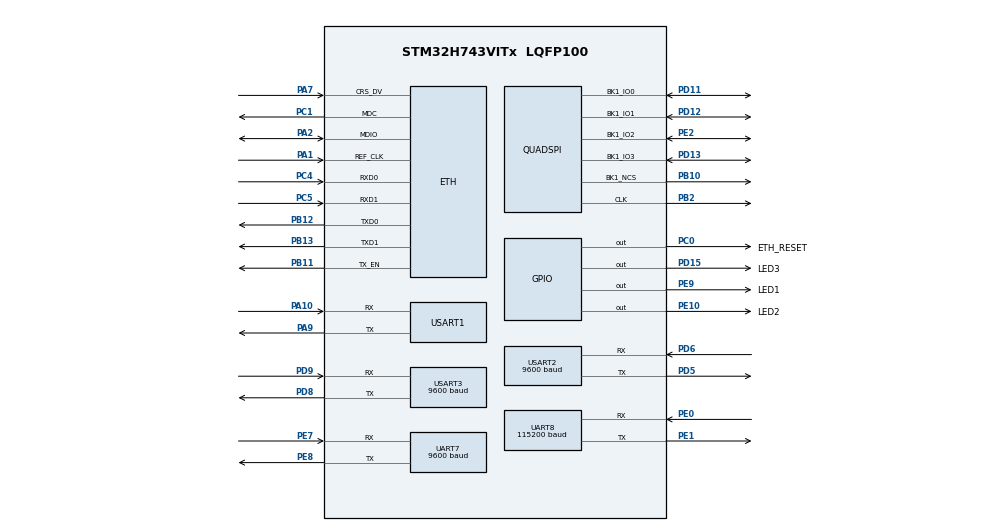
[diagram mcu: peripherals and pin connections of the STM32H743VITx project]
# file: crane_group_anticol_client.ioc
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CORTEX_M7.AccessPermission_S-Cortex_Memory_Protection_Unit_Region1_Settings_S=MPU_REGION_FULL_ACCESS
CORTEX_M7.AccessPermission_S-Cortex_Memory_Protection_Unit_Region2_Settings_S=MPU_REGION_FULL_ACCESS
CORTEX_M7.BaseAddress_S-Cortex_Memory_Protection_Unit_Region1_Settings_S=0x30020000
CORTEX_M7.BaseAddress_S-Cortex_Memory_Protection_Unit_Region2_Settings_S=0x30040000
CORTEX_M7.CPU_DCache=Enabled
CORTEX_M7.CPU_ICache=Enabled
CORTEX_M7.DisableExec_S-Cortex_Memory_Protection_Unit_Region1_Settings_S=MPU_INSTRUCTION_ACCESS_DISABLE
CORTEX_M7.DisableExec_S-Cortex_Memory_Protection_Unit_Region2_Settings_S=MPU_INSTRUCTION_ACCESS_DISABLE
CORTEX_M7.Enable_S-Cortex_Memory_Protection_Unit_Region1_Settings_S=MPU_REGION_ENABLE
CORTEX_M7.Enable_S-Cortex_Memory_Protection_Unit_Region2_Settings_S=MPU_REGION_ENABLE
CORTEX_M7.IsBufferable_S-Cortex_Memory_Protection_Unit_Region2_Settings_S=MPU_ACCESS_BUFFERABLE
CORTEX_M7.IsShareable_S-Cortex_Memory_Protection_Unit_Region2_Settings_S=MPU_ACCESS_SHAREABLE
CORTEX_M7.Size_S-Cortex_Memory_Protection_Unit_Region1_Settings_S=MPU_REGION_SIZE_128KB
CORTEX_M7.Size_S-Cortex_Memory_Protection_Unit_Region2_Settings_S=MPU_REGION_SIZE_512B
CORTEX_M7.TypeExtField_S-Cortex_Memory_Protection_Unit_Region1_Settings_S=MPU_TEX_LEVEL1
CORTEX_M7.default_mode_Activation=1
Dma.Request0=UART7_RX
Dma.Request1=UART7_TX
Dma.Request2=USART1_RX
Dma.Request3=USART1_TX
Dma.Request4=USART2_RX
Dma.Request5=USART2_TX
Dma.Request6=UART8_RX
Dma.Request7=UART8_TX
Dma.Request8=USART3_RX
Dma.Request9=USART3_TX
Dma.UART7_RX.0.Direction=DMA_PERIPH_TO_MEMORY
Dma.UART7_RX.0.EventEnable=DISABLE
Dma.UART7_RX.0.FIFOMode=DMA_FIFOMODE_DISABLE
Dma.UART7_RX.0.Instance=DMA1_Stream0
Dma.UART7_RX.0.MemDataAlignment=DMA_MDATAALIGN_BYTE
Dma.UART7_RX.0.MemInc=DMA_MINC_ENABLE
Dma.UART7_RX.0.Mode=DMA_NORMAL
Dma.UART7_RX.0.PeriphDataAlignment=DMA_PDATAALIGN_BYTE
Dma.UART7_RX.0.PeriphInc=DMA_PINC_DISABLE
Dma.UART7_RX.0.Polarity=HAL_DMAMUX_REQ_GEN_RISING
Dma.UART7_RX.0.Priority=DMA_PRIORITY_VERY_HIGH
Dma.UART7_RX.0.RequestNumber=1
Dma.UART7_RX.0.SignalID=NONE
Dma.UART7_RX.0.SyncEnable=DISABLE
Dma.UART7_RX.0.SyncPolarity=HAL_DMAMUX_SYNC_NO_EVENT
Dma.UART7_RX.0.SyncRequestNumber=1
Dma.UART7_RX.0.SyncSignalID=NONE
Dma.UART7_TX.1.Direction=DMA_MEMORY_TO_PERIPH
Dma.UART7_TX.1.EventEnable=DISABLE
Dma.UART7_TX.1.FIFOMode=DMA_FIFOMODE_DISABLE
Dma.UART7_TX.1.Instance=DMA1_Stream1
Dma.UART7_TX.1.MemDataAlignment=DMA_MDATAALIGN_BYTE
Dma.UART7_TX.1.MemInc=DMA_MINC_ENABLE
Dma.UART7_TX.1.Mode=DMA_NORMAL
Dma.UART7_TX.1.PeriphDataAlignment=DMA_PDATAALIGN_BYTE
Dma.UART7_TX.1.PeriphInc=DMA_PINC_DISABLE
Dma.UART7_TX.1.Polarity=HAL_DMAMUX_REQ_GEN_RISING
Dma.UART7_TX.1.Priority=DMA_PRIORITY_VERY_HIGH
Dma.UART7_TX.1.RequestNumber=1
Dma.UART7_TX.1.SignalID=NONE
Dma.UART7_TX.1.SyncEnable=DISABLE
Dma.UART7_TX.1.SyncPolarity=HAL_DMAMUX_SYNC_NO_EVENT
Dma.UART7_TX.1.SyncRequestNumber=1
Dma.UART7_TX.1.SyncSignalID=NONE
Dma.UART8_RX.6.Direction=DMA_PERIPH_TO_MEMORY
Dma.UART8_RX.6.EventEnable=DISABLE
Dma.UART8_RX.6.FIFOMode=DMA_FIFOMODE_DISABLE
Dma.UART8_RX.6.Instance=DMA1_Stream6
Dma.UART8_RX.6.MemDataAlignment=DMA_MDATAALIGN_BYTE
Dma.UART8_RX.6.MemInc=DMA_MINC_ENABLE
Dma.UART8_RX.6.Mode=DMA_NORMAL
Dma.UART8_RX.6.PeriphDataAlignment=DMA_PDATAALIGN_BYTE
Dma.UART8_RX.6.PeriphInc=DMA_PINC_DISABLE
Dma.UART8_RX.6.Polarity=HAL_DMAMUX_REQ_GEN_RISING
Dma.UART8_RX.6.Priority=DMA_PRIORITY_LOW
Dma.UART8_RX.6.RequestNumber=1
Dma.UART8_RX.6.SignalID=NONE
Dma.UART8_RX.6.SyncEnable=DISABLE
Dma.UART8_RX.6.SyncPolarity=HAL_DMAMUX_SYNC_NO_EVENT
Dma.UART8_RX.6.SyncRequestNumber=1
Dma.UART8_RX.6.SyncSignalID=NONE
Dma.UART8_TX.7.Direction=DMA_MEMORY_TO_PERIPH
Dma.UART8_TX.7.EventEnable=DISABLE
Dma.UART8_TX.7.FIFOMode=DMA_FIFOMODE_DISABLE
Dma.UART8_TX.7.Instance=DMA1_Stream7
Dma.UART8_TX.7.MemDataAlignment=DMA_MDATAALIGN_BYTE
Dma.UART8_TX.7.MemInc=DMA_MINC_ENABLE
Dma.UART8_TX.7.Mode=DMA_NORMAL
Dma.UART8_TX.7.PeriphDataAlignment=DMA_PDATAALIGN_BYTE
Dma.UART8_TX.7.PeriphInc=DMA_PINC_DISABLE
Dma.UART8_TX.7.Polarity=HAL_DMAMUX_REQ_GEN_RISING
Dma.UART8_TX.7.Priority=DMA_PRIORITY_LOW
Dma.UART8_TX.7.RequestNumber=1
Dma.UART8_TX.7.SignalID=NONE
Dma.UART8_TX.7.SyncEnable=DISABLE
Dma.UART8_TX.7.SyncPolarity=HAL_DMAMUX_SYNC_NO_EVENT
Dma.UART8_TX.7.SyncRequestNumber=1
Dma.UART8_TX.7.SyncSignalID=NONE
Dma.USART1_RX.2.Direction=DMA_PERIPH_TO_MEMORY
Dma.USART1_RX.2.EventEnable=DISABLE
Dma.USART1_RX.2.FIFOMode=DMA_FIFOMODE_DISABLE
Dma.USART1_RX.2.Instance=DMA1_Stream2
Dma.USART1_RX.2.MemDataAlignment=DMA_MDATAALIGN_BYTE
Dma.USART1_RX.2.MemInc=DMA_MINC_ENABLE
Dma.USART1_RX.2.Mode=DMA_NORMAL
Dma.USART1_RX.2.PeriphDataAlignment=DMA_PDATAALIGN_BYTE
Dma.USART1_RX.2.PeriphInc=DMA_PINC_DISABLE
Dma.USART1_RX.2.Polarity=HAL_DMAMUX_REQ_GEN_RISING
Dma.USART1_RX.2.Priority=DMA_PRIORITY_LOW
Dma.USART1_RX.2.RequestNumber=1
Dma.USART1_RX.2.SignalID=NONE
Dma.USART1_RX.2.SyncEnable=DISABLE
Dma.USART1_RX.2.SyncPolarity=HAL_DMAMUX_SYNC_NO_EVENT
Dma.USART1_RX.2.SyncRequestNumber=1
Dma.USART1_RX.2.SyncSignalID=NONE
Dma.USART1_TX.3.Direction=DMA_MEMORY_TO_PERIPH
Dma.USART1_TX.3.EventEnable=DISABLE
Dma.USART1_TX.3.FIFOMode=DMA_FIFOMODE_DISABLE
Dma.USART1_TX.3.Instance=DMA1_Stream3
Dma.USART1_TX.3.MemDataAlignment=DMA_MDATAALIGN_BYTE
Dma.USART1_TX.3.MemInc=DMA_MINC_ENABLE
Dma.USART1_TX.3.Mode=DMA_NORMAL
Dma.USART1_TX.3.PeriphDataAlignment=DMA_PDATAALIGN_BYTE
Dma.USART1_TX.3.PeriphInc=DMA_PINC_DISABLE
Dma.USART1_TX.3.Polarity=HAL_DMAMUX_REQ_GEN_RISING
Dma.USART1_TX.3.Priority=DMA_PRIORITY_LOW
Dma.USART1_TX.3.RequestNumber=1
Dma.USART1_TX.3.SignalID=NONE
Dma.USART1_TX.3.SyncEnable=DISABLE
Dma.USART1_TX.3.SyncPolarity=HAL_DMAMUX_SYNC_NO_EVENT
Dma.USART1_TX.3.SyncRequestNumber=1
Dma.USART1_TX.3.SyncSignalID=NONE
Dma.USART2_RX.4.Direction=DMA_PERIPH_TO_MEMORY
Dma.USART2_RX.4.EventEnable=DISABLE
Dma.USART2_RX.4.FIFOMode=DMA_FIFOMODE_DISABLE
Dma.USART2_RX.4.Instance=DMA1_Stream4
Dma.USART2_RX.4.MemDataAlignment=DMA_MDATAALIGN_BYTE
Dma.USART2_RX.4.MemInc=DMA_MINC_ENABLE
Dma.USART2_RX.4.Mode=DMA_NORMAL
Dma.USART2_RX.4.PeriphDataAlignment=DMA_PDATAALIGN_BYTE
Dma.USART2_RX.4.PeriphInc=DMA_PINC_DISABLE
Dma.USART2_RX.4.Polarity=HAL_DMAMUX_REQ_GEN_RISING
Dma.USART2_RX.4.Priority=DMA_PRIORITY_HIGH
Dma.USART2_RX.4.RequestNumber=1
Dma.USART2_RX.4.SignalID=NONE
Dma.USART2_RX.4.SyncEnable=DISABLE
Dma.USART2_RX.4.SyncPolarity=HAL_DMAMUX_SYNC_NO_EVENT
Dma.USART2_RX.4.SyncRequestNumber=1
Dma.USART2_RX.4.SyncSignalID=NONE
Dma.USART2_TX.5.Direction=DMA_MEMORY_TO_PERIPH
Dma.USART2_TX.5.EventEnable=DISABLE
Dma.USART2_TX.5.FIFOMode=DMA_FIFOMODE_DISABLE
Dma.USART2_TX.5.Instance=DMA1_Stream5
Dma.USART2_TX.5.MemDataAlignment=DMA_MDATAALIGN_BYTE
Dma.USART2_TX.5.MemInc=DMA_MINC_ENABLE
Dma.USART2_TX.5.Mode=DMA_NORMAL
Dma.USART2_TX.5.PeriphDataAlignment=DMA_PDATAALIGN_BYTE
Dma.USART2_TX.5.PeriphInc=DMA_PINC_DISABLE
Dma.USART2_TX.5.Polarity=HAL_DMAMUX_REQ_GEN_RISING
Dma.USART2_TX.5.Priority=DMA_PRIORITY_HIGH
Dma.USART2_TX.5.RequestNumber=1
Dma.USART2_TX.5.SignalID=NONE
Dma.USART2_TX.5.SyncEnable=DISABLE
Dma.USART2_TX.5.SyncPolarity=HAL_DMAMUX_SYNC_NO_EVENT
Dma.USART2_TX.5.SyncRequestNumber=1
Dma.USART2_TX.5.SyncSignalID=NONE
Dma.USART3_RX.8.Direction=DMA_PERIPH_TO_MEMORY
Dma.USART3_RX.8.EventEnable=DISABLE
Dma.USART3_RX.8.FIFOMode=DMA_FIFOMODE_DISABLE
Dma.USART3_RX.8.Instance=DMA2_Stream0
Dma.USART3_RX.8.MemDataAlignment=DMA_MDATAALIGN_BYTE
Dma.USART3_RX.8.MemInc=DMA_MINC_ENABLE
Dma.USART3_RX.8.Mode=DMA_NORMAL
Dma.USART3_RX.8.PeriphDataAlignment=DMA_PDATAALIGN_BYTE
Dma.USART3_RX.8.PeriphInc=DMA_PINC_DISABLE
Dma.USART3_RX.8.Polarity=HAL_DMAMUX_REQ_GEN_RISING
Dma.USART3_RX.8.Priority=DMA_PRIORITY_LOW
Dma.USART3_RX.8.RequestNumber=1
Dma.USART3_RX.8.SignalID=NONE
Dma.USART3_RX.8.SyncEnable=DISABLE
Dma.USART3_RX.8.SyncPolarity=HAL_DMAMUX_SYNC_NO_EVENT
Dma.USART3_RX.8.SyncRequestNumber=1
Dma.USART3_RX.8.SyncSignalID=NONE
Dma.USART3_TX.9.Direction=DMA_MEMORY_TO_PERIPH
Dma.USART3_TX.9.EventEnable=DISABLE
Dma.USART3_TX.9.FIFOMode=DMA_FIFOMODE_DISABLE
Dma.USART3_TX.9.Instance=DMA2_Stream1
Dma.USART3_TX.9.MemDataAlignment=DMA_MDATAALIGN_BYTE
Dma.USART3_TX.9.MemInc=DMA_MINC_ENABLE
Dma.USART3_TX.9.Mode=DMA_NORMAL
Dma.USART3_TX.9.PeriphDataAlignment=DMA_PDATAALIGN_BYTE
Dma.USART3_TX.9.PeriphInc=DMA_PINC_DISABLE
Dma.USART3_TX.9.Polarity=HAL_DMAMUX_REQ_GEN_RISING
Dma.USART3_TX.9.Priority=DMA_PRIORITY_LOW
Dma.USART3_TX.9.RequestNumber=1
Dma.USART3_TX.9.SignalID=NONE
Dma.USART3_TX.9.SyncEnable=DISABLE
Dma.USART3_TX.9.SyncPolarity=HAL_DMAMUX_SYNC_NO_EVENT
Dma.USART3_TX.9.SyncRequestNumber=1
Dma.USART3_TX.9.SyncSignalID=NONE
ETH.MediaInterface=HAL_ETH_RMII_MODE
FREERTOS.Tasks01=defaultTask,24,2048,StartDefaultTask,Default,NULL,Dynamic,NULL,NULL
FREERTOS.configCHECK_FOR_STACK_OVERFLOW=1
FREERTOS.configTOTAL_HEAP_SIZE=131072
FREERTOS.configUSE_NEWLIB_REENTRANT=1
IWDG1.Prescaler=IWDG_PRESCALER_256
LWIP.BSP.number=1
LWIP.DEFAULT_ACCEPTMBOX_SIZE=12
LWIP.GATEWAY_ADDRESS=192.168.042.001
LWIP.IP_ADDRESS=192.168.042.033
LWIP.LWIP_DHCP=1
LWIP.LWIP_DNS=1
LWIP.LWIP_RAM_HEAP_POINTER=0x30020000
LWIP.LWIP_SNTP=1
LWIP.LWIP_SO_RCVTIMEO=1
LWIP.LWIP_SO_SNDTIMEO=1
LWIP.LWIP_TCPIP_CORE_LOCKING=1
LWIP.LWIP_TCP_KEEPALIVE=1
LWIP.MEMP_NUM_NETCONN=15
LWIP.MEMP_NUM_SYS_TIMEOUT=20
LWIP.MEMP_NUM_TCP_PCB=20
LWIP.MEMP_NUM_TCP_SEG=17
LWIP.MEMP_NUM_UDP_PCB=20
LWIP.MEM_SIZE=131048
LWIP.NETMASK_ADDRESS=255.255.255.000
LWIP.SO_REUSE=1
LWIP.TCPIP_THREAD_STACKSIZE=4096
LWIP.TCP_MSS=1460
LWIP.TCP_SND_BUF=5840
LWIP.TCP_WND_UPDATE_THRESHOLD=1460
LWIP.Version=v2.1.2_Cube
LWIP0.BSP.STBoard=false
LWIP0.BSP.api=BSP_COMPONENT_DRIVER
LWIP0.BSP.component=LAN8742
LWIP0.BSP.instance=LAN8742
LWIP0.BSP.name=Driver_PHY
LWIP0.BSP.semaphore=S_LAN8742
LWIP0.BSP.solution=LAN8742
Mcu.Family=STM32H7
Mcu.Name=STM32H743VITx
Mcu.Package=LQFP100
NVIC.DMA1_Stream0_IRQn=true\:5\:0\:false\:false\:true\:true\:false\:true\:true
NVIC.DMA1_Stream1_IRQn=true\:5\:0\:false\:false\:true\:true\:false\:true\:true
NVIC.DMA1_Stream2_IRQn=true\:5\:0\:false\:false\:true\:true\:false\:true\:true
NVIC.DMA1_Stream3_IRQn=true\:5\:0\:false\:false\:true\:true\:false\:true\:true
NVIC.DMA1_Stream4_IRQn=true\:5\:0\:false\:false\:true\:true\:false\:true\:true
NVIC.DMA1_Stream5_IRQn=true\:5\:0\:false\:false\:true\:true\:false\:true\:true
NVIC.DMA1_Stream6_IRQn=true\:5\:0\:false\:false\:true\:true\:false\:true\:true
NVIC.DMA1_Stream7_IRQn=true\:5\:0\:false\:false\:true\:true\:false\:true\:true
NVIC.DMA2_Stream0_IRQn=true\:5\:0\:false\:false\:true\:true\:false\:true\:true
NVIC.DMA2_Stream1_IRQn=true\:5\:0\:false\:false\:true\:true\:false\:true\:true
NVIC.ETH_IRQn=true\:5\:0\:false\:false\:true\:true\:true\:true\:true
NVIC.PriorityGroup=NVIC_PRIORITYGROUP_4
NVIC.TIM6_DAC_IRQn=true\:15\:0\:false\:false\:true\:false\:false\:true\:true
NVIC.TimeBase=TIM6_DAC_IRQn
NVIC.TimeBaseIP=TIM6
NVIC.UART7_IRQn=true\:5\:0\:false\:false\:true\:true\:true\:true\:true
NVIC.UART8_IRQn=true\:5\:0\:false\:false\:true\:true\:true\:true\:true
NVIC.USART1_IRQn=true\:5\:0\:false\:false\:true\:true\:true\:true\:true
NVIC.USART2_IRQn=true\:5\:0\:false\:false\:true\:true\:true\:true\:true
NVIC.USART3_IRQn=true\:5\:0\:false\:false\:true\:true\:true\:true\:true
PA1.GPIO_Speed=GPIO_SPEED_FREQ_VERY_HIGH
PA1.Mode=RMII
PA1.Signal=ETH_REF_CLK
PA10.Mode=Asynchronous
PA10.Signal=USART1_RX
PA2.GPIO_Speed=GPIO_SPEED_FREQ_VERY_HIGH
PA2.Mode=RMII
PA2.Signal=ETH_MDIO
PA7.GPIO_Speed=GPIO_SPEED_FREQ_VERY_HIGH
PA7.Mode=RMII
PA7.Signal=ETH_CRS_DV
PA9.Mode=Asynchronous
PA9.Signal=USART1_TX
PB10.GPIO_Speed=GPIO_SPEED_FREQ_VERY_HIGH
PB10.Mode=Single Bank 1
PB10.Signal=QUADSPI_BK1_NCS
PB11.GPIO_Speed=GPIO_SPEED_FREQ_VERY_HIGH
PB11.Mode=RMII
PB11.Signal=ETH_TX_EN
PB12.GPIO_Speed=GPIO_SPEED_FREQ_VERY_HIGH
PB12.Mode=RMII
PB12.Signal=ETH_TXD0
PB13.GPIO_Speed=GPIO_SPEED_FREQ_VERY_HIGH
PB13.Mode=RMII
PB13.Signal=ETH_TXD1
PB2.GPIO_Speed=GPIO_SPEED_FREQ_VERY_HIGH
PB2.Mode=Single Bank 1
PB2.Signal=QUADSPI_CLK
PC0.GPIO_Label=ETH_RESET
PC0.Signal=GPIO_Output
PC1.GPIO_Speed=GPIO_SPEED_FREQ_VERY_HIGH
PC1.Mode=RMII
PC1.Signal=ETH_MDC
PC4.GPIO_Speed=GPIO_SPEED_FREQ_VERY_HIGH
PC4.Mode=RMII
PC4.Signal=ETH_RXD0
PC5.GPIO_Speed=GPIO_SPEED_FREQ_VERY_HIGH
PC5.Mode=RMII
PC5.Signal=ETH_RXD1
PD11.GPIO_Speed=GPIO_SPEED_FREQ_VERY_HIGH
PD11.Mode=Single Bank 1
PD11.Signal=QUADSPI_BK1_IO0
PD12.GPIO_Speed=GPIO_SPEED_FREQ_VERY_HIGH
PD12.Mode=Single Bank 1
PD12.Signal=QUADSPI_BK1_IO1
PD13.GPIO_Speed=GPIO_SPEED_FREQ_VERY_HIGH
PD13.Mode=Single Bank 1
PD13.Signal=QUADSPI_BK1_IO3
PD15.GPIO_Label=LED3
PD15.Signal=GPIO_Output
PD5.GPIO_Speed=GPIO_SPEED_FREQ_VERY_HIGH
PD5.Mode=Asynchronous
PD5.Signal=USART2_TX
PD6.GPIO_Speed=GPIO_SPEED_FREQ_VERY_HIGH
PD6.Mode=Asynchronous
PD6.Signal=USART2_RX
PD8.Mode=Asynchronous
PD8.Signal=USART3_TX
PD9.Mode=Asynchronous
PD9.Signal=USART3_RX
PE0.Mode=Asynchronous
PE0.Signal=UART8_RX
PE1.Mode=Asynchronous
PE1.Signal=UART8_TX
PE10.GPIO_Label=LED2
PE10.GPIO_PuPd=GPIO_PULLUP
PE10.PinState=GPIO_PIN_SET
PE10.Signal=GPIO_Output
PE2.GPIO_Speed=GPIO_SPEED_FREQ_VERY_HIGH
PE2.Mode=Single Bank 1
PE2.Signal=QUADSPI_BK1_IO2
PE7.Mode=Asynchronous
PE7.Signal=UART7_RX
PE8.Mode=Asynchronous
PE8.Signal=UART7_TX
PE9.GPIO_Label=LED1
PE9.GPIO_PuPd=GPIO_PULLUP
PE9.PinState=GPIO_PIN_SET
PE9.Signal=GPIO_Output
PH0-OSC_IN\ (PH0).Mode=HSE-External-Clock-Source
PH0-OSC_IN\ (PH0).Signal=RCC_OSC_IN
ProjectManager.HeapSize=0x4000
ProjectManager.StackSize=0x4000
ProjectManager.TargetToolchain=STM32CubeIDE
QUADSPI.ChipSelectHighTime=QSPI_CS_HIGH_TIME_2_CYCLE
QUADSPI.ClockPrescaler=2
QUADSPI.FlashSize=24
QUADSPI.SampleShifting=QSPI_SAMPLE_SHIFTING_HALFCYCLE
RCC.ADCFreq_Value=100000000
RCC.APB1Freq_Value=100000000
RCC.APB2Freq_Value=100000000
RCC.APB3Freq_Value=100000000
RCC.APB4Freq_Value=100000000
RCC.CortexFreq_Value=400000000
RCC.D1PPRE=RCC_APB3_DIV2
RCC.D2PPRE1=RCC_APB1_DIV2
RCC.D2PPRE2=RCC_APB2_DIV2
RCC.D3PPRE=RCC_APB4_DIV2
RCC.DIVN1=400
RCC.DIVN2=100
RCC.DIVN3=30
RCC.HCLKFreq_Value=200000000
RCC.HPRE=RCC_HCLK_DIV2
RCC.SYSCLKFreq_VALUE=400000000
RCC.SYSCLKSource=RCC_SYSCLKSOURCE_PLLCLK
RCC.USBFreq_Value=400000000
UART7.BaudRate=9600
UART8.BaudRate=115200
USART1.VirtualMode-Asynchronous=VM_ASYNC
USART2.BaudRate=9600
USART2.Parity=PARITY_EVEN
USART2.VirtualMode-Asynchronous=VM_ASYNC
USART2.WordLength=WORDLENGTH_9B
USART3.BaudRate=9600
USART3.Parity=PARITY_EVEN
USART3.VirtualMode-Asynchronous=VM_ASYNC
USART3.WordLength=WORDLENGTH_9B
VP_FREERTOS_VS_CMSIS_V2.Mode=CMSIS_V2
VP_IWDG1_VS_IWDG.Mode=IWDG_Activate
VP_LWIP_VS_Enabled.Mode=Enabled
VP_MEMORYMAP_VS_MEMORYMAP.Mode=CurAppReg
VP_RTC_VS_RTC_Activate.Mode=RTC_Enabled
VP_RTC_VS_RTC_Calendar.Mode=RTC_Calendar
VP_SYS_VS_tim6.Mode=TIM6
board=custom

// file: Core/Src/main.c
/* USER CODE BEGIN Header */
/**
 ******************************************************************************
 * @file           : main.c
 * @brief          : Main program body
 ******************************************************************************
 * @attention
 *
 * Copyright (c) 2025 STMicroelectronics.
 * All rights reserved.
 *
 * This software is licensed under terms that can be found in the LICENSE file
 * in the root directory of this software component.
 * If no LICENSE file comes with this software, it is provided AS-IS.
 *
 ******************************************************************************
 */
/* USER CODE END Header */
#include "main.h"
#include "cmsis_os.h"

/* USER CODE BEGIN Includes */
#include "board_manage.h"
/* USER CODE END Includes */

/* USER CODE BEGIN PD */
#define LOG_D(fmt, ...) // printf("[D][%s:%d] " fmt, __func__, __LINE__, ##__VA_ARGS__)
#define LOG_I(fmt, ...) printf("[I][%s:%d] " fmt, __func__, __LINE__, ##__VA_ARGS__)
#define LOG_E(fmt, ...) printf("[E][%s:%d] " fmt, __func__, __LINE__, ##__VA_ARGS__)
/* USER CODE END PD */

IWDG_HandleTypeDef hiwdg1;

QSPI_HandleTypeDef hqspi;

RTC_HandleTypeDef hrtc;

UART_HandleTypeDef huart7;
UART_HandleTypeDef huart8;
UART_HandleTypeDef huart1;
UART_HandleTypeDef huart2;
UART_HandleTypeDef huart3;
DMA_HandleTypeDef hdma_uart7_rx;
DMA_HandleTypeDef hdma_uart7_tx;
DMA_HandleTypeDef hdma_uart8_rx;
DMA_HandleTypeDef hdma_uart8_tx;
DMA_HandleTypeDef hdma_usart1_rx;
DMA_HandleTypeDef hdma_usart1_tx;
DMA_HandleTypeDef hdma_usart2_rx;
DMA_HandleTypeDef hdma_usart2_tx;
DMA_HandleTypeDef hdma_usart3_rx;
DMA_HandleTypeDef hdma_usart3_tx;

/* Definitions for defaultTask */
osThreadId_t defaultTaskHandle;
const osThreadAttr_t defaultTask_attributes = {
  .name = "defaultTask",
  .stack_size = 2048 * 4,
  .priority = (osPriority_t) osPriorityNormal,
};

void SystemClock_Config(void);
static void MPU_Config(void);
static void MX_GPIO_Init(void);
static void MX_DMA_Init(void);
static void MX_USART1_UART_Init(void);
static void MX_UART7_Init(void);
static void MX_UART8_Init(void);
static void MX_USART2_UART_Init(void);
static void MX_USART3_UART_Init(void);
static void MX_RTC_Init(void);
static void MX_QUADSPI_Init(void);
static void MX_IWDG1_Init(void);
void StartDefaultTask(void *argument);

int main(void)
{

  /* MPU Configuration--------------------------------------------------------*/
  MPU_Config();

  /* Enable the CPU Cache */

  /* Enable I-Cache---------------------------------------------------------*/
  SCB_EnableICache();

  /* Enable D-Cache---------------------------------------------------------*/
  SCB_EnableDCache();

  /* MCU Configuration--------------------------------------------------------*/

  /* Reset of all peripherals, Initializes the Flash interface and the Systick. */
  HAL_Init();

  /* Configure the system clock */
  SystemClock_Config();

  /* Initialize all configured peripherals */
  MX_GPIO_Init();
  MX_DMA_Init();
  MX_USART1_UART_Init();
  MX_UART7_Init();
  MX_UART8_Init();
  MX_USART2_UART_Init();
  MX_USART3_UART_Init();
  MX_RTC_Init();
  MX_QUADSPI_Init();
  MX_IWDG1_Init();
  /* USER CODE BEGIN 2 */
  board_setup_components();
  /* USER CODE END 2 */

  /* Init scheduler */
  osKernelInitialize();

  /* Create the thread(s) */
  /* creation of defaultTask */
  defaultTaskHandle = osThreadNew(StartDefaultTask, NULL, &defaultTask_attributes);

  /* USER CODE BEGIN RTOS_THREADS */
  /* add threads, ... */
  board_create_user_tasks();
  /* USER CODE END RTOS_THREADS */

  /* Start scheduler */
  osKernelStart();

  /* We should never get here as control is now taken by the scheduler */

  /* Infinite loop */
  while (1)
  {

  }
}

void SystemClock_Config(void)
{
  RCC_OscInitTypeDef RCC_OscInitStruct = {0};
  RCC_ClkInitTypeDef RCC_ClkInitStruct = {0};

  /** Supply configuration update enable
  */
  HAL_PWREx_ConfigSupply(PWR_LDO_SUPPLY);

  /** Configure the main internal regulator output voltage
  */
  __HAL_PWR_VOLTAGESCALING_CONFIG(PWR_REGULATOR_VOLTAGE_SCALE1);

  while(!__HAL_PWR_GET_FLAG(PWR_FLAG_VOSRDY)) {}

  /** Initializes the RCC Oscillators according to the specified parameters
  * in the RCC_OscInitTypeDef structure.
  */
  RCC_OscInitStruct.OscillatorType = RCC_OSCILLATORTYPE_HSI|RCC_OSCILLATORTYPE_LSI;
  RCC_OscInitStruct.HSIState = RCC_HSI_DIV1;
  RCC_OscInitStruct.HSICalibrationValue = RCC_HSICALIBRATION_DEFAULT;
  RCC_OscInitStruct.LSIState = RCC_LSI_ON;
  RCC_OscInitStruct.PLL.PLLState = RCC_PLL_ON;
  RCC_OscInitStruct.PLL.PLLSource = RCC_PLLSOURCE_HSI;
  RCC_OscInitStruct.PLL.PLLM = 32;
  RCC_OscInitStruct.PLL.PLLN = 400;
  RCC_OscInitStruct.PLL.PLLP = 2;
  RCC_OscInitStruct.PLL.PLLQ = 2;
  RCC_OscInitStruct.PLL.PLLR = 2;
  RCC_OscInitStruct.PLL.PLLRGE = RCC_PLL1VCIRANGE_1;
  RCC_OscInitStruct.PLL.PLLVCOSEL = RCC_PLL1VCOWIDE;
  RCC_OscInitStruct.PLL.PLLFRACN = 0;
  if (HAL_RCC_OscConfig(&RCC_OscInitStruct) != HAL_OK)
  {
    Error_Handler();
  }

  /** Initializes the CPU, AHB and APB buses clocks
  */
  RCC_ClkInitStruct.ClockType = RCC_CLOCKTYPE_HCLK|RCC_CLOCKTYPE_SYSCLK
                              |RCC_CLOCKTYPE_PCLK1|RCC_CLOCKTYPE_PCLK2
                              |RCC_CLOCKTYPE_D3PCLK1|RCC_CLOCKTYPE_D1PCLK1;
  RCC_ClkInitStruct.SYSCLKSource = RCC_SYSCLKSOURCE_PLLCLK;
  RCC_ClkInitStruct.SYSCLKDivider = RCC_SYSCLK_DIV1;
  RCC_ClkInitStruct.AHBCLKDivider = RCC_HCLK_DIV2;
  RCC_ClkInitStruct.APB3CLKDivider = RCC_APB3_DIV2;
  RCC_ClkInitStruct.APB1CLKDivider = RCC_APB1_DIV2;
  RCC_ClkInitStruct.APB2CLKDivider = RCC_APB2_DIV2;
  RCC_ClkInitStruct.APB4CLKDivider = RCC_APB4_DIV2;

  if (HAL_RCC_ClockConfig(&RCC_ClkInitStruct, FLASH_LATENCY_2) != HAL_OK)
  {
    Error_Handler();
  }
}

static void MX_IWDG1_Init(void)
{

  hiwdg1.Instance = IWDG1;
  hiwdg1.Init.Prescaler = IWDG_PRESCALER_256;
  hiwdg1.Init.Window = 4095;
  hiwdg1.Init.Reload = 4095;
  if (HAL_IWDG_Init(&hiwdg1) != HAL_OK)
  {
    Error_Handler();
  }

}

static void MX_QUADSPI_Init(void)
{

  /* QUADSPI parameter configuration*/
  hqspi.Instance = QUADSPI;
  hqspi.Init.ClockPrescaler = 2;
  hqspi.Init.FifoThreshold = 1;
  hqspi.Init.SampleShifting = QSPI_SAMPLE_SHIFTING_HALFCYCLE;
  hqspi.Init.FlashSize = 24;
  hqspi.Init.ChipSelectHighTime = QSPI_CS_HIGH_TIME_2_CYCLE;
  hqspi.Init.ClockMode = QSPI_CLOCK_MODE_0;
  hqspi.Init.FlashID = QSPI_FLASH_ID_1;
  hqspi.Init.DualFlash = QSPI_DUALFLASH_DISABLE;
  if (HAL_QSPI_Init(&hqspi) != HAL_OK)
  {
    Error_Handler();
  }

}

static void MX_RTC_Init(void)
{

  RTC_TimeTypeDef sTime = {0};
  RTC_DateTypeDef sDate = {0};

  /** Initialize RTC Only
  */
  hrtc.Instance = RTC;
  hrtc.Init.HourFormat = RTC_HOURFORMAT_24;
  hrtc.Init.AsynchPrediv = 127;
  hrtc.Init.SynchPrediv = 255;
  hrtc.Init.OutPut = RTC_OUTPUT_DISABLE;
  hrtc.Init.OutPutPolarity = RTC_OUTPUT_POLARITY_HIGH;
  hrtc.Init.OutPutType = RTC_OUTPUT_TYPE_OPENDRAIN;
  hrtc.Init.OutPutRemap = RTC_OUTPUT_REMAP_NONE;
  if (HAL_RTC_Init(&hrtc) != HAL_OK)
  {
    Error_Handler();
  }

  /** Initialize RTC and set the Time and Date
  */
  sTime.Hours = 0x0;
  sTime.Minutes = 0x0;
  sTime.Seconds = 0x0;
  sTime.DayLightSaving = RTC_DAYLIGHTSAVING_NONE;
  sTime.StoreOperation = RTC_STOREOPERATION_RESET;
  if (HAL_RTC_SetTime(&hrtc, &sTime, RTC_FORMAT_BCD) != HAL_OK)
  {
    Error_Handler();
  }
  sDate.WeekDay = RTC_WEEKDAY_MONDAY;
  sDate.Month = RTC_MONTH_JANUARY;
  sDate.Date = 0x1;
  sDate.Year = 0x0;

  if (HAL_RTC_SetDate(&hrtc, &sDate, RTC_FORMAT_BCD) != HAL_OK)
  {
    Error_Handler();
  }

}

static void MX_UART7_Init(void)
{

  huart7.Instance = UART7;
  huart7.Init.BaudRate = 9600;
  huart7.Init.WordLength = UART_WORDLENGTH_8B;
  huart7.Init.StopBits = UART_STOPBITS_1;
  huart7.Init.Parity = UART_PARITY_NONE;
  huart7.Init.Mode = UART_MODE_TX_RX;
  huart7.Init.HwFlowCtl = UART_HWCONTROL_NONE;
  huart7.Init.OverSampling = UART_OVERSAMPLING_16;
  huart7.Init.OneBitSampling = UART_ONE_BIT_SAMPLE_DISABLE;
  huart7.Init.ClockPrescaler = UART_PRESCALER_DIV1;
  huart7.AdvancedInit.AdvFeatureInit = UART_ADVFEATURE_NO_INIT;
  if (HAL_UART_Init(&huart7) != HAL_OK)
  {
    Error_Handler();
  }
  if (HAL_UARTEx_SetTxFifoThreshold(&huart7, UART_TXFIFO_THRESHOLD_1_8) != HAL_OK)
  {
    Error_Handler();
  }
  if (HAL_UARTEx_SetRxFifoThreshold(&huart7, UART_RXFIFO_THRESHOLD_1_8) != HAL_OK)
  {
    Error_Handler();
  }
  if (HAL_UARTEx_DisableFifoMode(&huart7) != HAL_OK)
  {
    Error_Handler();
  }

}

static void MX_UART8_Init(void)
{

  huart8.Instance = UART8;
  huart8.Init.BaudRate = 115200;
  huart8.Init.WordLength = UART_WORDLENGTH_8B;
  huart8.Init.StopBits = UART_STOPBITS_1;
  huart8.Init.Parity = UART_PARITY_NONE;
  huart8.Init.Mode = UART_MODE_TX_RX;
  huart8.Init.HwFlowCtl = UART_HWCONTROL_NONE;
  huart8.Init.OverSampling = UART_OVERSAMPLING_16;
  huart8.Init.OneBitSampling = UART_ONE_BIT_SAMPLE_DISABLE;
  huart8.Init.ClockPrescaler = UART_PRESCALER_DIV1;
  huart8.AdvancedInit.AdvFeatureInit = UART_ADVFEATURE_NO_INIT;
  if (HAL_UART_Init(&huart8) != HAL_OK)
  {
    Error_Handler();
  }
  if (HAL_UARTEx_SetTxFifoThreshold(&huart8, UART_TXFIFO_THRESHOLD_1_8) != HAL_OK)
  {
    Error_Handler();
  }
  if (HAL_UARTEx_SetRxFifoThreshold(&huart8, UART_RXFIFO_THRESHOLD_1_8) != HAL_OK)
  {
    Error_Handler();
  }
  if (HAL_UARTEx_DisableFifoMode(&huart8) != HAL_OK)
  {
    Error_Handler();
  }

}

static void MX_USART1_UART_Init(void)
{

  huart1.Instance = USART1;
  huart1.Init.BaudRate = 115200;
  huart1.Init.WordLength = UART_WORDLENGTH_8B;
  huart1.Init.StopBits = UART_STOPBITS_1;
  huart1.Init.Parity = UART_PARITY_NONE;
  huart1.Init.Mode = UART_MODE_TX_RX;
  huart1.Init.HwFlowCtl = UART_HWCONTROL_NONE;
  huart1.Init.OverSampling = UART_OVERSAMPLING_16;
  huart1.Init.OneBitSampling = UART_ONE_BIT_SAMPLE_DISABLE;
  huart1.Init.ClockPrescaler = UART_PRESCALER_DIV1;
  huart1.AdvancedInit.AdvFeatureInit = UART_ADVFEATURE_NO_INIT;
  if (HAL_UART_Init(&huart1) != HAL_OK)
  {
    Error_Handler();
  }
  if (HAL_UARTEx_SetTxFifoThreshold(&huart1, UART_TXFIFO_THRESHOLD_1_8) != HAL_OK)
  {
    Error_Handler();
  }
  if (HAL_UARTEx_SetRxFifoThreshold(&huart1, UART_RXFIFO_THRESHOLD_1_8) != HAL_OK)
  {
    Error_Handler();
  }
  if (HAL_UARTEx_DisableFifoMode(&huart1) != HAL_OK)
  {
    Error_Handler();
  }

}

static void MX_USART2_UART_Init(void)
{

  huart2.Instance = USART2;
  huart2.Init.BaudRate = 9600;
  huart2.Init.WordLength = UART_WORDLENGTH_9B;
  huart2.Init.StopBits = UART_STOPBITS_1;
  huart2.Init.Parity = UART_PARITY_EVEN;
  huart2.Init.Mode = UART_MODE_TX_RX;
  huart2.Init.HwFlowCtl = UART_HWCONTROL_NONE;
  huart2.Init.OverSampling = UART_OVERSAMPLING_16;
  huart2.Init.OneBitSampling = UART_ONE_BIT_SAMPLE_DISABLE;
  huart2.Init.ClockPrescaler = UART_PRESCALER_DIV1;
  huart2.AdvancedInit.AdvFeatureInit = UART_ADVFEATURE_NO_INIT;
  if (HAL_UART_Init(&huart2) != HAL_OK)
  {
    Error_Handler();
  }
  if (HAL_UARTEx_SetTxFifoThreshold(&huart2, UART_TXFIFO_THRESHOLD_1_8) != HAL_OK)
  {
    Error_Handler();
  }
  if (HAL_UARTEx_SetRxFifoThreshold(&huart2, UART_RXFIFO_THRESHOLD_1_8) != HAL_OK)
  {
    Error_Handler();
  }
  if (HAL_UARTEx_DisableFifoMode(&huart2) != HAL_OK)
  {
    Error_Handler();
  }

}

static void MX_USART3_UART_Init(void)
{

  huart3.Instance = USART3;
  huart3.Init.BaudRate = 9600;
  huart3.Init.WordLength = UART_WORDLENGTH_9B;
  huart3.Init.StopBits = UART_STOPBITS_1;
  huart3.Init.Parity = UART_PARITY_EVEN;
  huart3.Init.Mode = UART_MODE_TX_RX;
  huart3.Init.HwFlowCtl = UART_HWCONTROL_NONE;
  huart3.Init.OverSampling = UART_OVERSAMPLING_16;
  huart3.Init.OneBitSampling = UART_ONE_BIT_SAMPLE_DISABLE;
  huart3.Init.ClockPrescaler = UART_PRESCALER_DIV1;
  huart3.AdvancedInit.AdvFeatureInit = UART_ADVFEATURE_NO_INIT;
  if (HAL_UART_Init(&huart3) != HAL_OK)
  {
    Error_Handler();
  }
  if (HAL_UARTEx_SetTxFifoThreshold(&huart3, UART_TXFIFO_THRESHOLD_1_8) != HAL_OK)
  {
    Error_Handler();
  }
  if (HAL_UARTEx_SetRxFifoThreshold(&huart3, UART_RXFIFO_THRESHOLD_1_8) != HAL_OK)
  {
    Error_Handler();
  }
  if (HAL_UARTEx_DisableFifoMode(&huart3) != HAL_OK)
  {
    Error_Handler();
  }

}

static void MX_DMA_Init(void)
{

  /* DMA controller clock enable */
  __HAL_RCC_DMA1_CLK_ENABLE();
  __HAL_RCC_DMA2_CLK_ENABLE();

  /* DMA interrupt init */
  /* DMA1_Stream0_IRQn interrupt configuration */
  HAL_NVIC_SetPriority(DMA1_Stream0_IRQn, 5, 0);
  HAL_NVIC_EnableIRQ(DMA1_Stream0_IRQn);
  /* DMA1_Stream1_IRQn interrupt configuration */
  HAL_NVIC_SetPriority(DMA1_Stream1_IRQn, 5, 0);
  HAL_NVIC_EnableIRQ(DMA1_Stream1_IRQn);
  /* DMA1_Stream2_IRQn interrupt configuration */
  HAL_NVIC_SetPriority(DMA1_Stream2_IRQn, 5, 0);
  HAL_NVIC_EnableIRQ(DMA1_Stream2_IRQn);
  /* DMA1_Stream3_IRQn interrupt configuration */
  HAL_NVIC_SetPriority(DMA1_Stream3_IRQn, 5, 0);
  HAL_NVIC_EnableIRQ(DMA1_Stream3_IRQn);
  /* DMA1_Stream4_IRQn interrupt configuration */
  HAL_NVIC_SetPriority(DMA1_Stream4_IRQn, 5, 0);
  HAL_NVIC_EnableIRQ(DMA1_Stream4_IRQn);
  /* DMA1_Stream5_IRQn interrupt configuration */
  HAL_NVIC_SetPriority(DMA1_Stream5_IRQn, 5, 0);
  HAL_NVIC_EnableIRQ(DMA1_Stream5_IRQn);
  /* DMA1_Stream6_IRQn interrupt configuration */
  HAL_NVIC_SetPriority(DMA1_Stream6_IRQn, 5, 0);
  HAL_NVIC_EnableIRQ(DMA1_Stream6_IRQn);
  /* DMA1_Stream7_IRQn interrupt configuration */
  HAL_NVIC_SetPriority(DMA1_Stream7_IRQn, 5, 0);
  HAL_NVIC_EnableIRQ(DMA1_Stream7_IRQn);
  /* DMA2_Stream0_IRQn interrupt configuration */
  HAL_NVIC_SetPriority(DMA2_Stream0_IRQn, 5, 0);
  HAL_NVIC_EnableIRQ(DMA2_Stream0_IRQn);
  /* DMA2_Stream1_IRQn interrupt configuration */
  HAL_NVIC_SetPriority(DMA2_Stream1_IRQn, 5, 0);
  HAL_NVIC_EnableIRQ(DMA2_Stream1_IRQn);

}

static void MX_GPIO_Init(void)
{
  GPIO_InitTypeDef GPIO_InitStruct = {0};

  /* GPIO Ports Clock Enable */
  __HAL_RCC_GPIOE_CLK_ENABLE();
  __HAL_RCC_GPIOH_CLK_ENABLE();
  __HAL_RCC_GPIOC_CLK_ENABLE();
  __HAL_RCC_GPIOA_CLK_ENABLE();
  __HAL_RCC_GPIOB_CLK_ENABLE();
  __HAL_RCC_GPIOD_CLK_ENABLE();

  /*Configure GPIO pin Output Level */
  HAL_GPIO_WritePin(ETH_RESET_GPIO_Port, ETH_RESET_Pin, GPIO_PIN_RESET);

  /*Configure GPIO pin Output Level */
  HAL_GPIO_WritePin(GPIOE, LED1_Pin|LED2_Pin, GPIO_PIN_SET);

  /*Configure GPIO pin Output Level */
  HAL_GPIO_WritePin(LED3_GPIO_Port, LED3_Pin, GPIO_PIN_RESET);

  /*Configure GPIO pin : ETH_RESET_Pin */
  GPIO_InitStruct.Pin = ETH_RESET_Pin;
  GPIO_InitStruct.Mode = GPIO_MODE_OUTPUT_PP;
  GPIO_InitStruct.Pull = GPIO_NOPULL;
  GPIO_InitStruct.Speed = GPIO_SPEED_FREQ_LOW;
  HAL_GPIO_Init(ETH_RESET_GPIO_Port, &GPIO_InitStruct);

  /*Configure GPIO pins : LED1_Pin LED2_Pin */
  GPIO_InitStruct.Pin = LED1_Pin|LED2_Pin;
  GPIO_InitStruct.Mode = GPIO_MODE_OUTPUT_PP;
  GPIO_InitStruct.Pull = GPIO_PULLUP;
  GPIO_InitStruct.Speed = GPIO_SPEED_FREQ_LOW;
  HAL_GPIO_Init(GPIOE, &GPIO_InitStruct);

  /*Configure GPIO pin : LED3_Pin */
  GPIO_InitStruct.Pin = LED3_Pin;
  GPIO_InitStruct.Mode = GPIO_MODE_OUTPUT_PP;
  GPIO_InitStruct.Pull = GPIO_NOPULL;
  GPIO_InitStruct.Speed = GPIO_SPEED_FREQ_LOW;
  HAL_GPIO_Init(LED3_GPIO_Port, &GPIO_InitStruct);

}

void StartDefaultTask(void *argument)
{
  /* USER CODE BEGIN 5 */
  /* Infinite loop */
  for (;;)
  {
    osDelay(1000);
  }
  /* USER CODE END 5 */
}

 /* MPU Configuration */

void MPU_Config(void)
{
  MPU_Region_InitTypeDef MPU_InitStruct = {0};

  /* Disables the MPU */
  HAL_MPU_Disable();

  /** Initializes and configures the Region and the memory to be protected
  */
  MPU_InitStruct.Enable = MPU_REGION_ENABLE;
  MPU_InitStruct.Number = MPU_REGION_NUMBER0;
  MPU_InitStruct.BaseAddress = 0x0;
  MPU_InitStruct.Size = MPU_REGION_SIZE_4GB;
  MPU_InitStruct.SubRegionDisable = 0x87;
  MPU_InitStruct.TypeExtField = MPU_TEX_LEVEL0;
  MPU_InitStruct.AccessPermission = MPU_REGION_NO_ACCESS;
  MPU_InitStruct.DisableExec = MPU_INSTRUCTION_ACCESS_DISABLE;
  MPU_InitStruct.IsShareable = MPU_ACCESS_SHAREABLE;
  MPU_InitStruct.IsCacheable = MPU_ACCESS_NOT_CACHEABLE;
  MPU_InitStruct.IsBufferable = MPU_ACCESS_NOT_BUFFERABLE;

  HAL_MPU_ConfigRegion(&MPU_InitStruct);

  /** Initializes and configures the Region and the memory to be protected
  */
  MPU_InitStruct.Number = MPU_REGION_NUMBER1;
  MPU_InitStruct.BaseAddress = 0x30020000;
  MPU_InitStruct.Size = MPU_REGION_SIZE_128KB;
  MPU_InitStruct.SubRegionDisable = 0x0;
  MPU_InitStruct.TypeExtField = MPU_TEX_LEVEL1;
  MPU_InitStruct.AccessPermission = MPU_REGION_FULL_ACCESS;
  MPU_InitStruct.IsShareable = MPU_ACCESS_NOT_SHAREABLE;

  HAL_MPU_ConfigRegion(&MPU_InitStruct);

  /** Initializes and configures the Region and the memory to be protected
  */
  MPU_InitStruct.Number = MPU_REGION_NUMBER2;
  MPU_InitStruct.BaseAddress = 0x30040000;
  MPU_InitStruct.Size = MPU_REGION_SIZE_512B;
  MPU_InitStruct.TypeExtField = MPU_TEX_LEVEL0;
  MPU_InitStruct.IsShareable = MPU_ACCESS_SHAREABLE;
  MPU_InitStruct.IsBufferable = MPU_ACCESS_BUFFERABLE;

  HAL_MPU_ConfigRegion(&MPU_InitStruct);
  /* Enables the MPU */
  HAL_MPU_Enable(MPU_PRIVILEGED_DEFAULT);

}

void HAL_TIM_PeriodElapsedCallback(TIM_HandleTypeDef *htim)
{
  if (htim->Instance == TIM6)
  {
    HAL_IncTick();
  }
}

void Error_Handler(void)
{
  /* USER CODE BEGIN Error_Handler_Debug */
  /* User can add his own implementation to report the HAL error return state */
  __set_FAULTMASK(1);
  NVIC_SystemReset();
  while (1)
  {
  }
  /* USER CODE END Error_Handler_Debug */
}

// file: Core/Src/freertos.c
/* USER CODE BEGIN Header */
/**
  ******************************************************************************
  * File Name          : freertos.c
  * Description        : Code for freertos applications
  ******************************************************************************
  * @attention
  *
  * Copyright (c) 2025 STMicroelectronics.
  * All rights reserved.
  *
  * This software is licensed under terms that can be found in the LICENSE file
  * in the root directory of this software component.
  * If no LICENSE file comes with this software, it is provided AS-IS.
  *
  ******************************************************************************
  */
/* USER CODE END Header */

#include "FreeRTOS.h"
#include "task.h"
#include "main.h"

/* Hook prototypes */
void vApplicationStackOverflowHook(xTaskHandle xTask, signed char *pcTaskName);

/* USER CODE BEGIN 4 */
#include "board_manage.h"
void vApplicationStackOverflowHook(xTaskHandle xTask, signed char *pcTaskName)
{
   board_system_reset_force();
}
/* USER CODE END 4 */
